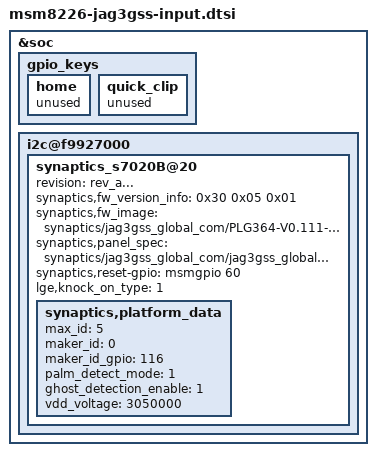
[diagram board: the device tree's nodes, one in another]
/* Copyright (c) 2013, LGE Electronics. All rights reserved.
 *
 * This program is free software; you can redistribute it and/or modify
 * it under the terms of the GNU General Public License version 2 and
 * only version 2 as published by the Free Software Foundation.
 *
 * This program is distributed in the hope that it will be useful,
 * but WITHOUT ANY WARRANTY; without even the implied warranty of
 * MERCHANTABILITY or FITNESS FOR A PARTICULAR PURPOSE.  See the
 * GNU General Public License for more details.
 */

&soc {
	gpio_keys {
		home {
			unused;
		};

		quick_clip {
			unused;
		};
	};

	i2c@f9927000 { /* BLSP1 QUP5 */
		synaptics_s7020B@20 {
			revision = "rev_a...";
			status = "ok";
			synaptics,fw_version_info = <0x30 0x05 0x01>;
			synaptics,fw_image = "synaptics/jag3gss_global_com/PLG364-V0.111-PR1674037-DS4.3.5.1.16_3005016F.img";
			synaptics,panel_spec = "synaptics/jag3gss_global_com/jag3gss_global_com_limit.txt";
			synaptics,reset-gpio = <&msmgpio 60 0x00>;
			lge,knock_on_type = <1>;
			synaptics,platform_data	{
				max_id = <5>;
				/*maker_id  disable(0), enable(1)*/
				maker_id = <0>;
				maker_id_gpio = <116>;
				palm_detect_mode = <1>;
				ghost_detection_enable = <1>;
                                vdd_voltage = <3050000>;
			};
		};

	};
};
